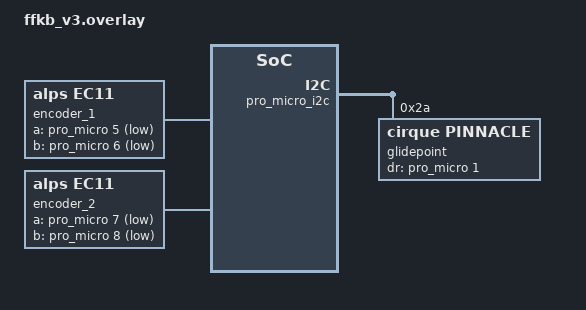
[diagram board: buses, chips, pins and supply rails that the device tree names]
/*
 * Copyright (c) 2021 The ZMK Contributors
 *
 * SPDX-License-Identifier: MIT
 */

#include <dt-bindings/zmk/matrix_transform.h>
#include <dt-bindings/zmk/input_transform.h>
#include <input/processors.dtsi>
#include <behaviors/input_gestures_accel.dtsi>

&pro_micro_i2c {
    status = "okay";
    glidepoint: glidepoint@2a {
        compatible = "cirque,pinnacle";
        reg = <0x2a>;
        status = "okay";
        dr-gpios = <&pro_micro 1 (GPIO_ACTIVE_HIGH)>;
        sensitivity = "1x";
        sleep;
        #no-taps;
    };
};

&pointer_accel {
    input-type = <INPUT_EV_REL>;  // For relative input devices
        track-remainders;             // Accumulate fractional movements
        min-factor = <1000>;          // 1.0x at very slow speeds
        max-factor = <4000>;         // 4.0x at fast speeds
        speed-threshold = <1200>;     // 1200 counts/sec for 1x
        speed-max = <6000>;          // 6000 counts/sec for max accel
        acceleration-exponent = <2>;  // Quadratic acceleration curve
};

/ {
    glidepoint_listener {
        compatible = "zmk,input-listener";
        device = <&glidepoint>;
        input-processors = <
            &pointer_accel
            &zip_xy_transform (INPUT_TRANSFORM_XY_SWAP | INPUT_TRANSFORM_X_INVERT | INPUT_TRANSFORM_Y_INVERT)
            &zip_temp_layer 6 500
        >;
        scroller {
            layers = <3>;
            input-processors = <
                &zip_xy_transform (INPUT_TRANSFORM_XY_SWAP)
                &zip_xy_scaler 1 4
                &zip_xy_to_scroll_mapper
            >;
        };
    };
    encoder_1: encoder_1 {
        compatible = "alps,ec11";
        a-gpios = <&pro_micro 5 (GPIO_ACTIVE_LOW | GPIO_PULL_UP)>;
        b-gpios = <&pro_micro 6 (GPIO_ACTIVE_LOW | GPIO_PULL_UP)>;
        steps = <15>;
        status = "okay";
    };

    // Right encoder
    encoder_2: encoder_2 {
        compatible = "alps,ec11";
        a-gpios = <&pro_micro 7 (GPIO_ACTIVE_LOW | GPIO_PULL_UP)>;
        b-gpios = <&pro_micro 8 (GPIO_ACTIVE_LOW | GPIO_PULL_UP)>;
        steps = <15>;
        status = "okay";
    };
};
